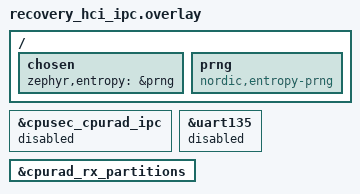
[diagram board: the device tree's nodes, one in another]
/*
 * Copyright (c) 2024 Nordic Semiconductor ASA
 *
 * SPDX-License-Identifier: LicenseRef-Nordic-5-Clause
 */

#include "nrf54h20dk_nrf54h20_memory_map.dtsi"

/ {
	chosen {
		zephyr,entropy = &prng;
	};

	/delete-node/ psa-rng;

	prng: prng {
		compatible = "nordic,entropy-prng";
		status = "okay";
	};

};

&cpusec_cpurad_ipc {
	status = "disabled";
};

&uart135 {
	status = "disabled";
};

&cpurad_rx_partitions {
	status = "okay";
};
